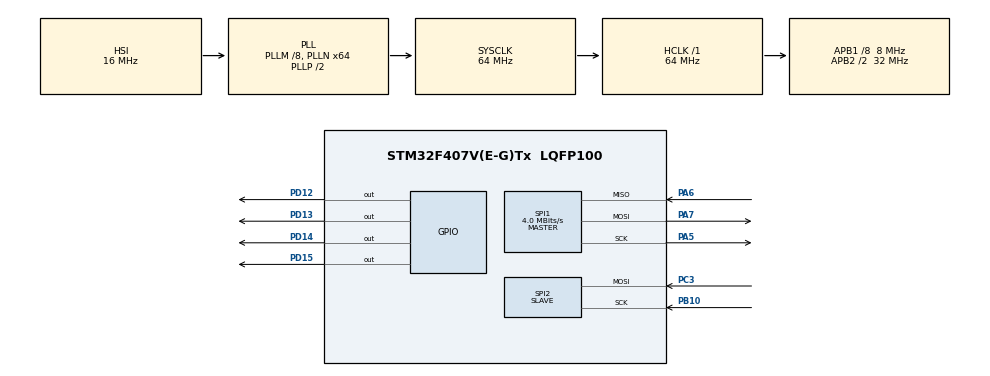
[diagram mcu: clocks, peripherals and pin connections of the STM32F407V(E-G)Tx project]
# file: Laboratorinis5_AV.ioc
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Mcu.Family=STM32F4
Mcu.Name=STM32F407V(E-G)Tx
Mcu.Package=LQFP100
NVIC.PriorityGroup=NVIC_PRIORITYGROUP_0
NVIC.SPI1_IRQn=true\:0\:0\:false\:false\:true\:true\:true\:true
NVIC.SPI2_IRQn=true\:0\:0\:false\:true\:true\:1\:true\:true\:true
NVIC.TIM2_IRQn=true\:0\:0\:false\:true\:true\:2\:true\:true\:true
PA13.Mode=Trace_Asynchronous_SW
PA13.Signal=SYS_JTMS-SWDIO
PA14.Mode=Trace_Asynchronous_SW
PA14.Signal=SYS_JTCK-SWCLK
PA5.Mode=Full_Duplex_Master
PA5.Signal=SPI1_SCK
PA6.Mode=Full_Duplex_Master
PA6.Signal=SPI1_MISO
PA7.Mode=Full_Duplex_Master
PA7.Signal=SPI1_MOSI
PB10.Mode=RX_Only_Simplex_Unidirect_Slave
PB10.Signal=SPI2_SCK
PB3.Mode=Trace_Asynchronous_SW
PB3.Signal=SYS_JTDO-SWO
PC3.Mode=RX_Only_Simplex_Unidirect_Slave
PC3.Signal=SPI2_MOSI
PD12.Signal=GPIO_Output
PD13.Signal=GPIO_Output
PD14.Signal=GPIO_Output
PD15.Signal=GPIO_Output
ProjectManager.HeapSize=0x200
ProjectManager.StackSize=0x400
ProjectManager.TargetToolchain=STM32CubeIDE
RCC.48MHZClocksFreq_Value=18285714.285714287
RCC.AHBFreq_Value=64000000
RCC.APB1CLKDivider=RCC_HCLK_DIV8
RCC.APB1Freq_Value=8000000
RCC.APB1TimFreq_Value=16000000
RCC.APB2CLKDivider=RCC_HCLK_DIV2
RCC.APB2Freq_Value=32000000
RCC.APB2TimFreq_Value=64000000
RCC.CortexFreq_Value=64000000
RCC.HCLKFreq_Value=64000000
RCC.HSE_VALUE=8000000
RCC.HSI_VALUE=16000000
RCC.LSE_VALUE=32768
RCC.PLLM=8
RCC.PLLN=64
RCC.PLLQ=7
RCC.SYSCLKFreq_VALUE=64000000
RCC.SYSCLKSource=RCC_SYSCLKSOURCE_PLLCLK
RCC.VCOOutputFreq_Value=128000000
SPI1.BaudRatePrescaler=SPI_BAUDRATEPRESCALER_8
SPI1.CalculateBaudRate=4.0 MBits/s
SPI1.Direction=SPI_DIRECTION_2LINES
SPI1.Mode=SPI_MODE_MASTER
SPI1.VirtualType=VM_MASTER
SPI2.Direction=SPI_DIRECTION_2LINES_RXONLY
SPI2.Mode=SPI_MODE_SLAVE
SPI2.VirtualType=VM_SLAVE
TIM2.Period=1000
TIM2.Prescaler=15999
VP_TIM2_VS_ClockSourceINT.Mode=Internal
board=STM32F407G-DISC1

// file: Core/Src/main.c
/* USER CODE BEGIN Header */
/**
  ******************************************************************************
  * @file           : main.c
  * @brief          : Main program body
  ******************************************************************************
  * @attention
  *
  * Copyright (c) 2023 STMicroelectronics.
  * All rights reserved.
  *
  * This software is licensed under terms that can be found in the LICENSE file
  * in the root directory of this software component.
  * If no LICENSE file comes with this software, it is provided AS-IS.
  *
  ******************************************************************************
  */
/* USER CODE END Header */
#include "main.h"

SPI_HandleTypeDef hspi1;
SPI_HandleTypeDef hspi2;

TIM_HandleTypeDef htim2;

/* USER CODE BEGIN PV */
//uint8_t tx[4] = {1,8,4,12};
//uint8_t rx[4];
//uint8_t number_13 = 0b1101;
//uint8_t number_15 = 0b1111;
/* USER CODE END PV */

void SystemClock_Config(void);
static void MX_GPIO_Init(void);
static void MX_SPI1_Init(void);
static void MX_SPI2_Init(void);
static void MX_TIM2_Init(void);
static void MX_NVIC_Init(void);

int main(void)
{

  /* MCU Configuration--------------------------------------------------------*/

  /* Reset of all peripherals, Initializes the Flash interface and the Systick. */
  HAL_Init();

  /* Configure the system clock */
  SystemClock_Config();

  /* Initialize all configured peripherals */
  MX_GPIO_Init();
  MX_SPI1_Init();
  MX_SPI2_Init();
  MX_TIM2_Init();

  /* Initialize interrupts */
  MX_NVIC_Init();
  /* USER CODE BEGIN 2 */
  //HAL_SPI_TransmitReceive(&hspi1, tx, rx, 4, 100);
  HAL_TIM_Base_Start_IT(&htim2);
  /* USER CODE END 2 */

  /* Infinite loop */
  while (1)
  {

  }
}

void SystemClock_Config(void)
{
  RCC_OscInitTypeDef RCC_OscInitStruct = {0};
  RCC_ClkInitTypeDef RCC_ClkInitStruct = {0};

  /** Configure the main internal regulator output voltage
  */
  __HAL_RCC_PWR_CLK_ENABLE();
  __HAL_PWR_VOLTAGESCALING_CONFIG(PWR_REGULATOR_VOLTAGE_SCALE1);

  /** Initializes the RCC Oscillators according to the specified parameters
  * in the RCC_OscInitTypeDef structure.
  */
  RCC_OscInitStruct.OscillatorType = RCC_OSCILLATORTYPE_HSI;
  RCC_OscInitStruct.HSIState = RCC_HSI_ON;
  RCC_OscInitStruct.HSICalibrationValue = RCC_HSICALIBRATION_DEFAULT;
  RCC_OscInitStruct.PLL.PLLState = RCC_PLL_ON;
  RCC_OscInitStruct.PLL.PLLSource = RCC_PLLSOURCE_HSI;
  RCC_OscInitStruct.PLL.PLLM = 8;
  RCC_OscInitStruct.PLL.PLLN = 64;
  RCC_OscInitStruct.PLL.PLLP = RCC_PLLP_DIV2;
  RCC_OscInitStruct.PLL.PLLQ = 7;
  if (HAL_RCC_OscConfig(&RCC_OscInitStruct) != HAL_OK)
  {
    Error_Handler();
  }

  /** Initializes the CPU, AHB and APB buses clocks
  */
  RCC_ClkInitStruct.ClockType = RCC_CLOCKTYPE_HCLK|RCC_CLOCKTYPE_SYSCLK
                              |RCC_CLOCKTYPE_PCLK1|RCC_CLOCKTYPE_PCLK2;
  RCC_ClkInitStruct.SYSCLKSource = RCC_SYSCLKSOURCE_PLLCLK;
  RCC_ClkInitStruct.AHBCLKDivider = RCC_SYSCLK_DIV1;
  RCC_ClkInitStruct.APB1CLKDivider = RCC_HCLK_DIV8;
  RCC_ClkInitStruct.APB2CLKDivider = RCC_HCLK_DIV2;

  if (HAL_RCC_ClockConfig(&RCC_ClkInitStruct, FLASH_LATENCY_2) != HAL_OK)
  {
    Error_Handler();
  }
}

/**
  * @brief NVIC Configuration.
  * @retval None
  */
static void MX_NVIC_Init(void)
{
  /* SPI2_IRQn interrupt configuration */
  HAL_NVIC_SetPriority(SPI2_IRQn, 0, 0);
  HAL_NVIC_EnableIRQ(SPI2_IRQn);
  /* TIM2_IRQn interrupt configuration */
  HAL_NVIC_SetPriority(TIM2_IRQn, 0, 0);
  HAL_NVIC_EnableIRQ(TIM2_IRQn);
}

static void MX_SPI1_Init(void)
{

  /* SPI1 parameter configuration*/
  hspi1.Instance = SPI1;
  hspi1.Init.Mode = SPI_MODE_MASTER;
  hspi1.Init.Direction = SPI_DIRECTION_2LINES;
  hspi1.Init.DataSize = SPI_DATASIZE_8BIT;
  hspi1.Init.CLKPolarity = SPI_POLARITY_LOW;
  hspi1.Init.CLKPhase = SPI_PHASE_1EDGE;
  hspi1.Init.NSS = SPI_NSS_SOFT;
  hspi1.Init.BaudRatePrescaler = SPI_BAUDRATEPRESCALER_8;
  hspi1.Init.FirstBit = SPI_FIRSTBIT_MSB;
  hspi1.Init.TIMode = SPI_TIMODE_DISABLE;
  hspi1.Init.CRCCalculation = SPI_CRCCALCULATION_DISABLE;
  hspi1.Init.CRCPolynomial = 10;
  if (HAL_SPI_Init(&hspi1) != HAL_OK)
  {
    Error_Handler();
  }

}

static void MX_SPI2_Init(void)
{

  /* SPI2 parameter configuration*/
  hspi2.Instance = SPI2;
  hspi2.Init.Mode = SPI_MODE_SLAVE;
  hspi2.Init.Direction = SPI_DIRECTION_2LINES_RXONLY;
  hspi2.Init.DataSize = SPI_DATASIZE_8BIT;
  hspi2.Init.CLKPolarity = SPI_POLARITY_LOW;
  hspi2.Init.CLKPhase = SPI_PHASE_1EDGE;
  hspi2.Init.NSS = SPI_NSS_SOFT;
  hspi2.Init.FirstBit = SPI_FIRSTBIT_MSB;
  hspi2.Init.TIMode = SPI_TIMODE_DISABLE;
  hspi2.Init.CRCCalculation = SPI_CRCCALCULATION_DISABLE;
  hspi2.Init.CRCPolynomial = 10;
  if (HAL_SPI_Init(&hspi2) != HAL_OK)
  {
    Error_Handler();
  }

}

static void MX_TIM2_Init(void)
{

  TIM_ClockConfigTypeDef sClockSourceConfig = {0};
  TIM_MasterConfigTypeDef sMasterConfig = {0};

  htim2.Instance = TIM2;
  htim2.Init.Prescaler = 15999;
  htim2.Init.CounterMode = TIM_COUNTERMODE_UP;
  htim2.Init.Period = 1000;
  htim2.Init.ClockDivision = TIM_CLOCKDIVISION_DIV1;
  htim2.Init.AutoReloadPreload = TIM_AUTORELOAD_PRELOAD_DISABLE;
  if (HAL_TIM_Base_Init(&htim2) != HAL_OK)
  {
    Error_Handler();
  }
  sClockSourceConfig.ClockSource = TIM_CLOCKSOURCE_INTERNAL;
  if (HAL_TIM_ConfigClockSource(&htim2, &sClockSourceConfig) != HAL_OK)
  {
    Error_Handler();
  }
  sMasterConfig.MasterOutputTrigger = TIM_TRGO_RESET;
  sMasterConfig.MasterSlaveMode = TIM_MASTERSLAVEMODE_DISABLE;
  if (HAL_TIMEx_MasterConfigSynchronization(&htim2, &sMasterConfig) != HAL_OK)
  {
    Error_Handler();
  }

}

static void MX_GPIO_Init(void)
{
  GPIO_InitTypeDef GPIO_InitStruct = {0};

  /* GPIO Ports Clock Enable */
  __HAL_RCC_GPIOC_CLK_ENABLE();
  __HAL_RCC_GPIOA_CLK_ENABLE();
  __HAL_RCC_GPIOB_CLK_ENABLE();
  __HAL_RCC_GPIOD_CLK_ENABLE();

  /*Configure GPIO pin Output Level */
  HAL_GPIO_WritePin(GPIOD, GPIO_PIN_12|GPIO_PIN_13|GPIO_PIN_14|GPIO_PIN_15, GPIO_PIN_RESET);

  /*Configure GPIO pins : PD12 PD13 PD14 PD15 */
  GPIO_InitStruct.Pin = GPIO_PIN_12|GPIO_PIN_13|GPIO_PIN_14|GPIO_PIN_15;
  GPIO_InitStruct.Mode = GPIO_MODE_OUTPUT_PP;
  GPIO_InitStruct.Pull = GPIO_NOPULL;
  GPIO_InitStruct.Speed = GPIO_SPEED_FREQ_LOW;
  HAL_GPIO_Init(GPIOD, &GPIO_InitStruct);

}

void Error_Handler(void)
{
  __disable_irq();
  while (1)
  {
  }
}
